# STM32F412CEU6 register map
File version: 1.0
Registers are 32-bit, access not given, reset 0x0 unless marked. A register's access mark holds for its fields unless they carry their own. Offsets are from the block's base; [hi:lo] are bit positions; {n}, {i} and the like mark numbered series.

## I2C1
Base 0x40005400
Same registers: I2C2 0x40005800, I2C3 0x40005C00, I2CFMP1 0x40006000
0x00 CR1
  [15] SWRST, [13] ALERT, [12] PEC, [11] POS, [10] ACK, [9] STOP, [8] START, [7] NOSTRETCH, [6] ENGC, [5] ENPEC, [4] ENARP, [3] SMBTYPE, [31:2] s, [1] SMBUS, [0] PE
0x04 CR2
  [12] LAST, [11] DMAEN, [10] ITBUFEN, [9] ITEVTEN, [8] ITERREN, [31:6] s, [5:0] FREQ
0x08 OAR1
  [15] ADDMODE, [31:10] s, [9:1] ADD, [0] ADD0
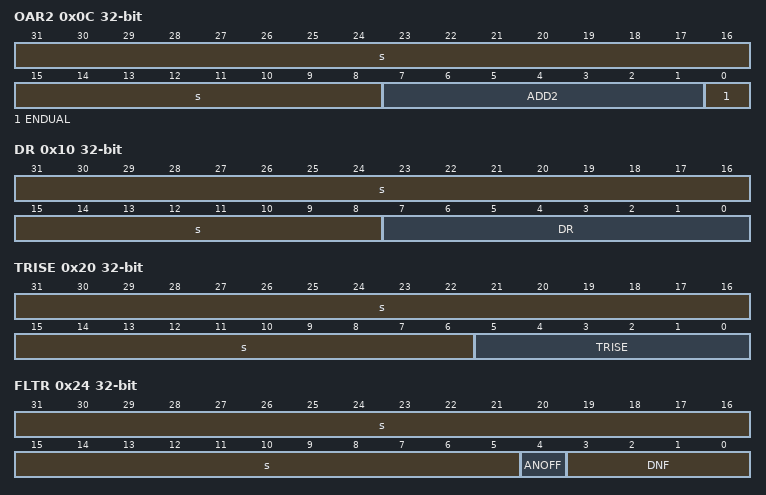
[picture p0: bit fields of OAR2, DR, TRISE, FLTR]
0x0C OAR2
  [31:8] s, [7:1] ADD2, [0] ENDUAL
0x10 DR
  [31:8] s, [7:0] DR
0x14 SR1
  [15] SMBALERT, [14] TIMEOUT, [12] PECERR, [11] OVR, [10] AF, [9] ARLO, [8] BERR, [7] TxE, [6] RxNE, [31:5] s, [4] STOPF, [3] ADD10, [2] BTF, [1] ADDR, [0] SB
0x18 SR2
  [15:8] PEC, [7] DUALF, [6] SMBHOST, [5] SMBDEFAUL, [4] GENCALL, [31:3] s, [2] TRA, [1] BUSY, [0] MSL
0x1C CCR
  [15] F/S, [14] DUTY, [31:12] s, [11:0] CCR
0x20 TRISE
  [31:6] s, [5:0] TRISE
0x24 FLTR
  [31:5] s, [4] ANOFF, [3:0] DNF

## CAN1
Base 0x40006400
Same registers: CAN2 0x40006800
0x00 MCR
  [16] DBF, [15] RESET, [31:8] s, [7] TTCM, [6] ABOM, [5] AWUM, [4] NART, [3] RFLM, [2] TXFP, [1] SLEEP, [0] INRQ
0x04 MSR
  [11] RX, [10] SAMP, [9] RXM, [8] TXM, [31:5] s, [4] SLAKI, [3] WKUI, [2] ERRI, [1] SLAK, [0] INAK
0x08 TSR
  [31:29] LOW, [28:26] TME, [25:24] CODE, [23] ABRQ2, [19] TERR2, [18] ALST2, [17] TXOK2, [16] RQCP2, [15] ABRQ1, [11] TERR1, [10] ALST1, [9] TXOK1, [8] RQCP1, [7] ABRQ0, [22:4] s, [3] TERR0, [2] ALST0, [1] TXOK0, [0] RQCP0
0x0C RF0R
  [5] RFOM0, [4] FOVR0, [3] FULL0, [31:2] s, [1:0] FMP0
0x10 RF1R
  [5] RFOM1, [4] FOVR1, [3] FULL1, [31:2] s, [1:0] FMP1
0x14 IER
  [17] SLKIE, [16] WKUIE, [15] ERRIE, [11] LECIE, [10] BOFIE, [9] EPVIE, [8] EWGIE, [31:7] s, [6] FOVIE1, [5] FFIE1, [4] FMPIE1, [3] FOVIE0, [2] FFIE0, [1] FMPIE0, [0] TMEIE
0x18 ESR
  [31:24] REC, [23:16] TEC, [6:4] LEC, [15:3] s, [2] BOFF, [1] EPVF, [0] EWGF
0x1C BTR
  [31] SILM, [30] LBKM, [25:24] SJW, [22:20] TS2, [19:16] TS1, [29:10] s, [9:0] BRP
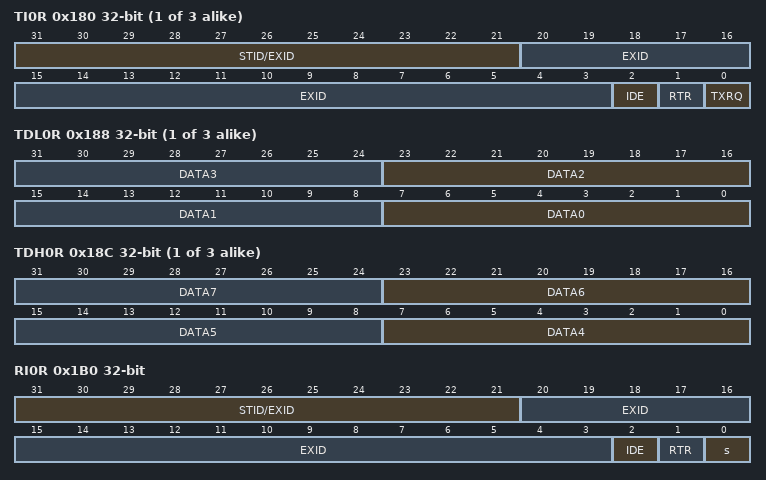
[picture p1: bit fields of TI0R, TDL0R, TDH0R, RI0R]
{0x180+0x10*i} TI{i}R (i=0..2)
  [31:21] STID/EXID, [20:3] EXID, [2] IDE, [1] RTR, [0] TXRQ
{0x184+0x10*i} TDT{i}R (i=0..2)
  [31:16] TIME, [8] TGT, [15:4] s, [3:0] DLC
{0x188+0x10*i} TDL{i}R (i=0..2)
  [8n+7:8n] DATA{n} (n=0..3)
{0x18C+0x10*i} TDH{i}R (i=0..2)
  [8n-25:8n-32] DATA{n} (n=4..7)
0x1B0 RI0R
  [31:21] STID/EXID, [20:3] EXID, [2] IDE, [1] RTR, [0] s
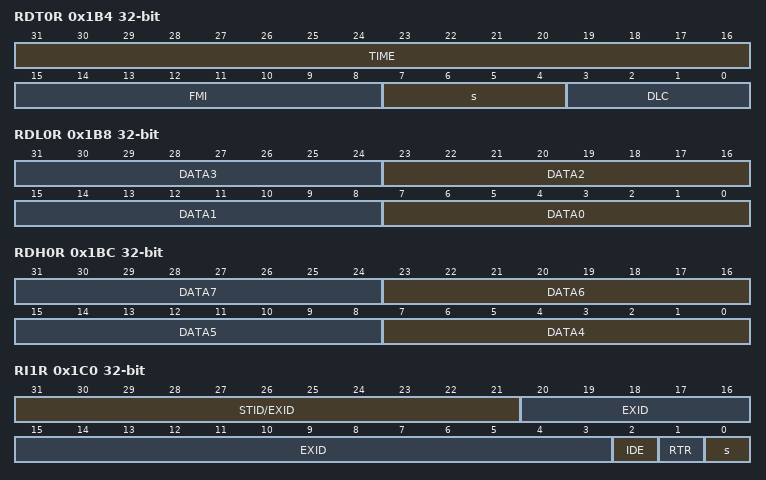
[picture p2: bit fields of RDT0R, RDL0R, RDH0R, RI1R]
0x1B4 RDT0R
  [31:16] TIME, [15:8] FMI, [7:4] s, [3:0] DLC
0x1B8 RDL0R
  [8n+7:8n] DATA{n} (n=0..3)
0x1BC RDH0R
  [8n-25:8n-32] DATA{n} (n=4..7)
0x1C0 RI1R
  [31:21] STID/EXID, [20:3] EXID, [2] IDE, [1] RTR, [0] s
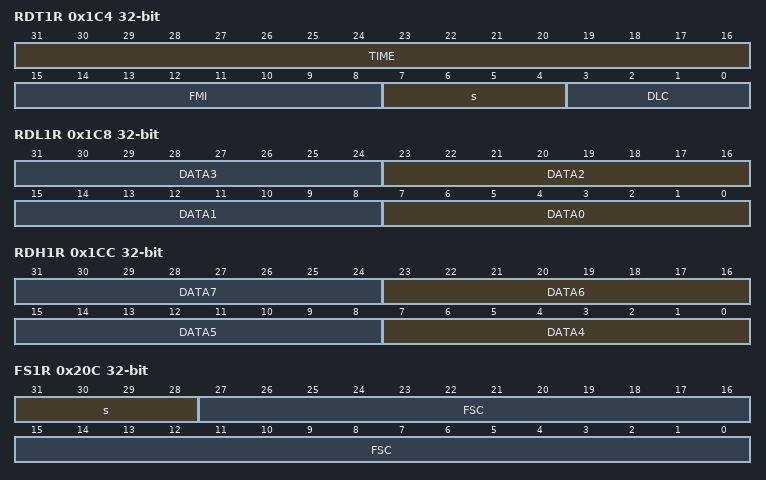
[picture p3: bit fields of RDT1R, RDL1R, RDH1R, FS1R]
0x1C4 RDT1R
  [31:16] TIME, [15:8] FMI, [7:4] s, [3:0] DLC
0x1C8 RDL1R
  [8n+7:8n] DATA{n} (n=0..3)
0x1CC RDH1R
  [8n-25:8n-32] DATA{n} (n=4..7)
0x20C FS1R
  [31:28] s, [27:0] FSC
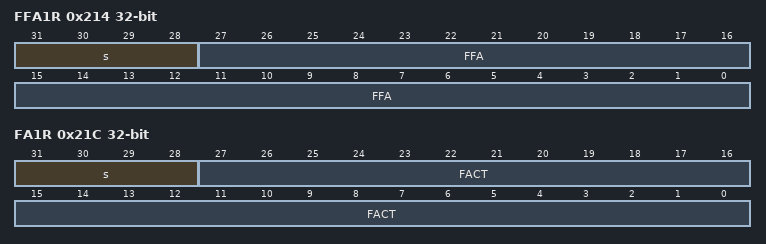
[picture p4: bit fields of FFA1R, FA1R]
0x214 FFA1R
  [31:28] s, [27:0] FFA
0x21C FA1R
  [31:28] s, [27:0] FACT
0x240 F0R1
  [31:0] FB
0x244 F0R2
  [31:0] FB
0x248 F1R1
  [31:0] FB
0x24C F1R2
  [31:0] FB
0x318 F27R1
  [31:0] FB
0x31C F27R2
  [31:0] FB

## PWR
Base 0x40007000
0x00 CR
0x04 CSR

## TIM1
Base 0x40010000
Same registers: TIM8 0x40010400
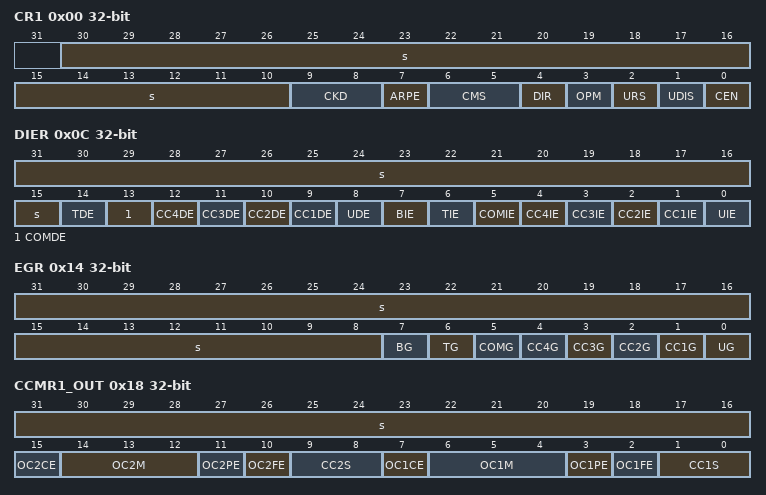
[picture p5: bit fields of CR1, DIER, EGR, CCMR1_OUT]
0x00 CR1
  [30:10] s, [9:8] CKD, [7] ARPE, [6:5] CMS, [4] DIR, [3] OPM, [2] URS, [1] UDIS, [0] CEN
0x04 CR2
  [2n+6] OIS{n} (n=1..4), [13] OIS3N, [11] OIS2N, [9] OIS1N, [7] TI1S, [6:4] MMS, [3] CCDS, [2] CCUS, [31:1] s, [0] CCPC
0x08 SMCR
  [15] ETP, [14] ECE, [13:12] ETPS, [11:8] ETF, [7] MSM, [6:4] TS, [31:3] s, [2:0] SMS
0x0C DIER
  [31:15] s, [14] TDE, [13] COMDE, [n+8] CC{n}DE (n=1..4), [8] UDE, [7] BIE, [6] TIE, [5] COMIE, [n] CC{n}IE (n=1..4), [0] UIE
0x10 SR
  [n+8] CC{n}OF (n=1..4), [31:8] s, [7] BIF, [6] TIF, [5] COMIF, [n] CC{n}IF (n=1..4), [0] UIF
0x14 EGR
  [31:8] s, [7] BG, [6] TG, [5] COMG, [n] CC{n}G (n=1..4), [0] UG
0x18 CCMR1_OUT
  [31:16] s, [15] OC2CE, [14:12] OC2M, [11] OC2PE, [10] OC2FE, [9:8] CC2S, [7] OC1CE, [6:4] OC1M, [3] OC1PE, [2] OC1FE, [1:0] CC1S
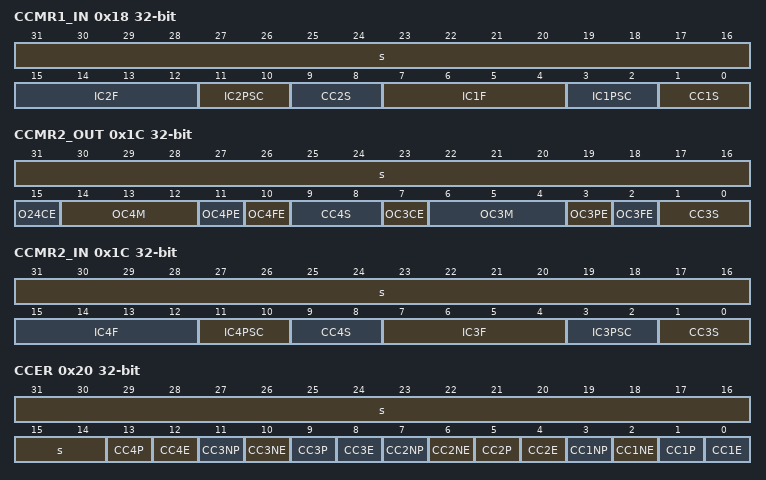
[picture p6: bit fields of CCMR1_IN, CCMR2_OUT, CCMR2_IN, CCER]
0x18 CCMR1_IN
  [31:16] s, [15:12] IC2F, [11:10] IC2PSC, [9:8] CC2S, [7:4] IC1F, [3:2] IC1PSC, [1:0] CC1S
0x1C CCMR2_OUT
  [31:16] s, [15] O24CE, [14:12] OC4M, [11] OC4PE, [10] OC4FE, [9:8] CC4S, [7] OC3CE, [6:4] OC3M, [3] OC3PE, [2] OC3FE, [1:0] CC3S
0x1C CCMR2_IN
  [31:16] s, [15:12] IC4F, [11:10] IC4PSC, [9:8] CC4S, [7:4] IC3F, [3:2] IC3PSC, [1:0] CC3S
0x20 CCER
  [31:14] s, [4n-3] CC{n}P (n=1..4), [4n-4] CC{n}E (n=1..4), [11] CC3NP, [10] CC3NE, [7] CC2NP, [6] CC2NE, [3] CC1NP, [2] CC1NE
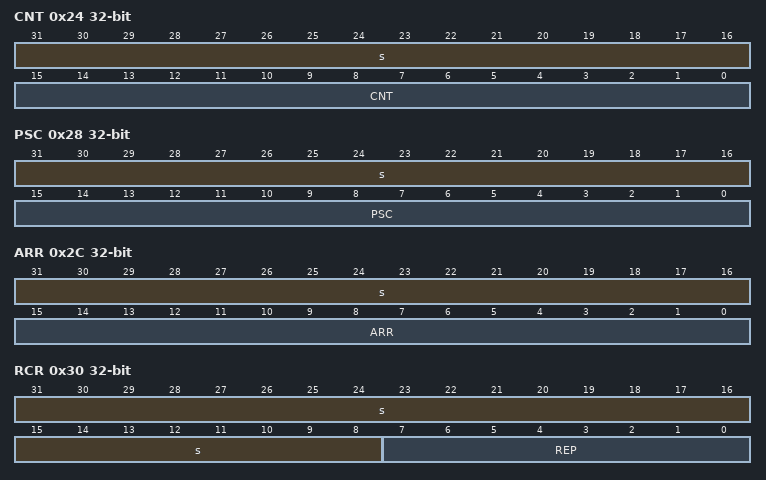
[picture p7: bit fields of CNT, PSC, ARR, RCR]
0x24 CNT
  [31:16] s, [15:0] CNT
0x28 PSC
  [31:16] s, [15:0] PSC
0x2C ARR
  [31:16] s, [15:0] ARR
0x30 RCR
  [31:8] s, [7:0] REP
0x34 CCR1
  [15:0] CCR1
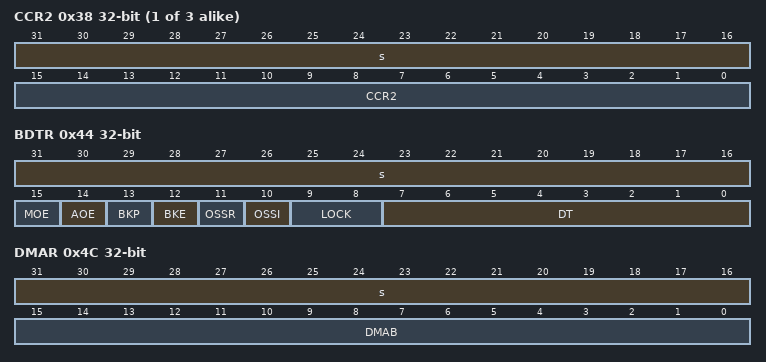
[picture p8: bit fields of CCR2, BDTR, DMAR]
{0x30+4i} CCR{i} (i=2..4)
  [31:16] s, [15:0] CCR{i}
0x44 BDTR
  [31:16] s, [15] MOE, [14] AOE, [13] BKP, [12] BKE, [11] OSSR, [10] OSSI, [9:8] LOCK, [7:0] DT
0x48 DCR
  [12:8] DBL, [31:5] s, [4:0] DBA
0x4C DMAR
  [31:16] s, [15:0] DMAB
